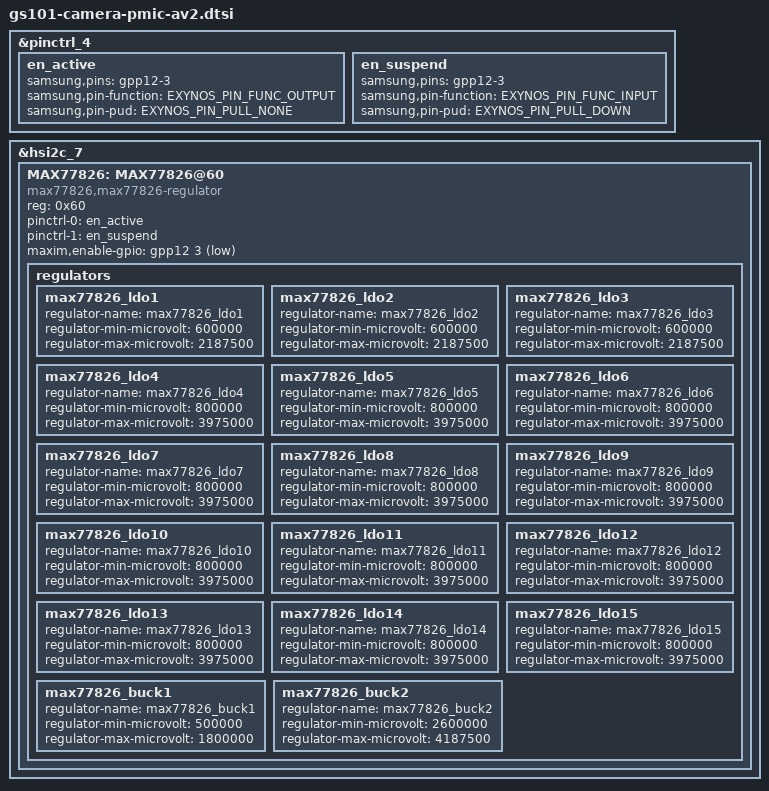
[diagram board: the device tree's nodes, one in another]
// SPDX-License-Identifier: GPL-2.0-only
/*
 * gs101 pmic device tree source for av2
 *
 * Copyright 2020 Google LLC.
 *
 */

#include <dt-bindings/pinctrl/samsung.h>

&pinctrl_4 {
	en_active: en_active {
		samsung,pins = "gpp12-3";
		samsung,pin-function = <EXYNOS_PIN_FUNC_OUTPUT>;
		samsung,pin-pud = <EXYNOS_PIN_PULL_NONE>;
	};

	en_suspend: en_suspend {
		samsung,pins = "gpp12-3";
		samsung,pin-function = <EXYNOS_PIN_FUNC_INPUT>;
		samsung,pin-pud = <EXYNOS_PIN_PULL_DOWN>;
	};
};

&hsi2c_7 {
	/* MAX77826 */
	status = "ok";
	#address-cells = <1>;
	#size-cells = <0>;
	MAX77826: MAX77826@60 {
		compatible = "max77826,max77826-regulator";
		reg = <0x60>;
		status = "ok";
		pinctrl-names = "active", "suspend";
		pinctrl-0 = <&en_active>;
		pinctrl-1 = <&en_suspend>;
		maxim,enable-gpio = <&gpp12 3 0x1>;

		regulators {
			max77826_ldo1: max77826_ldo1 {
				regulator-name = "max77826_ldo1";
				regulator-min-microvolt = <600000>;
				regulator-max-microvolt = <2187500>;
			};

			max77826_ldo2: max77826_ldo2 {
				regulator-name = "max77826_ldo2";
				regulator-min-microvolt = <600000>;
				regulator-max-microvolt = <2187500>;
			};

			max77826_ldo3: max77826_ldo3 {
				regulator-name = "max77826_ldo3";
				regulator-min-microvolt = <600000>;
				regulator-max-microvolt = <2187500>;
			};

			max77826_ldo4: max77826_ldo4 {
				regulator-name = "max77826_ldo4";
				regulator-min-microvolt = <800000>;
				regulator-max-microvolt = <3975000>;
			};

			max77826_ldo5: max77826_ldo5 {
				regulator-name = "max77826_ldo5";
				regulator-min-microvolt = <800000>;
				regulator-max-microvolt = <3975000>;
			};

			max77826_ldo6: max77826_ldo6 {
				regulator-name = "max77826_ldo6";
				regulator-min-microvolt = <800000>;
				regulator-max-microvolt = <3975000>;
			};

			max77826_ldo7: max77826_ldo7 {
				regulator-name = "max77826_ldo7";
				regulator-min-microvolt = <800000>;
				regulator-max-microvolt = <3975000>;
			};

			max77826_ldo8: max77826_ldo8 {
				regulator-name = "max77826_ldo8";
				regulator-min-microvolt = <800000>;
				regulator-max-microvolt = <3975000>;
			};

			max77826_ldo9: max77826_ldo9 {
				regulator-name = "max77826_ldo9";
				regulator-min-microvolt = <800000>;
				regulator-max-microvolt = <3975000>;
			};

			max77826_ldo10: max77826_ldo10 {
				regulator-name = "max77826_ldo10";
				regulator-min-microvolt = <800000>;
				regulator-max-microvolt = <3975000>;
			};

			max77826_ldo11: max77826_ldo11 {
				regulator-name = "max77826_ldo11";
				regulator-min-microvolt = <800000>;
				regulator-max-microvolt = <3975000>;
			};

			max77826_ldo12: max77826_ldo12 {
				regulator-name = "max77826_ldo12";
				regulator-min-microvolt = <800000>;
				regulator-max-microvolt = <3975000>;
			};

			max77826_ldo13: max77826_ldo13 {
				regulator-name = "max77826_ldo13";
				regulator-min-microvolt = <800000>;
				regulator-max-microvolt = <3975000>;
			};

			max77826_ldo14: max77826_ldo14 {
				regulator-name = "max77826_ldo14";
				regulator-min-microvolt = <800000>;
				regulator-max-microvolt = <3975000>;
			};

			max77826_ldo15: max77826_ldo15 {
				regulator-name = "max77826_ldo15";
				regulator-min-microvolt = <800000>;
				regulator-max-microvolt = <3975000>;
			};

			max77826_buck1: max77826_buck1 {
				regulator-name = "max77826_buck1";
				regulator-min-microvolt = <500000>;
				regulator-max-microvolt = <1800000>;
			};

			max77826_buck2: max77826_buck2 {
				regulator-name = "max77826_buck2";
				regulator-min-microvolt = <2600000>;
				regulator-max-microvolt = <4187500>;
			};
		};
	};
};
